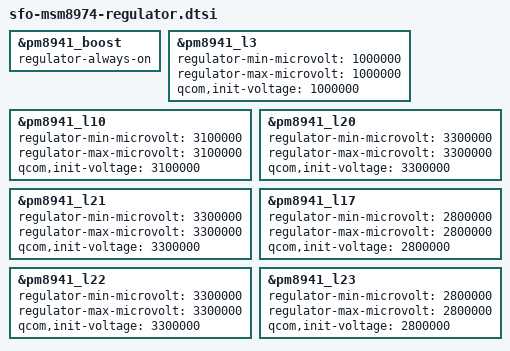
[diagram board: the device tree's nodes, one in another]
/* Copyright (c) 2012-2013, The Linux Foundation. All rights reserved.
 *
 * This program is free software; you can redistribute it and/or modify
 * it under the terms of the GNU General Public License version 2 and
 * only version 2 as published by the Free Software Foundation.
 *
 * This program is distributed in the hope that it will be useful,
 * but WITHOUT ANY WARRANTY; without even the implied warranty of
 * MERCHANTABILITY or FITNESS FOR A PARTICULAR PURPOSE.  See the
 * GNU General Public License for more details.
 */

&pm8941_boost {
            regulator-always-on;
};

&pm8941_l3 {
			regulator-min-microvolt = <1000000>;
			regulator-max-microvolt = <1000000>;
			qcom,init-voltage = <1000000>;
};

&pm8941_l10 {
			regulator-min-microvolt = <3100000>;
			regulator-max-microvolt = <3100000>;
			qcom,init-voltage = <3100000>;
};

&pm8941_l20 {
			regulator-min-microvolt = <3300000>;
			regulator-max-microvolt = <3300000>;
			qcom,init-voltage = <3300000>;
};

&pm8941_l21 {
			regulator-min-microvolt = <3300000>;
			regulator-max-microvolt = <3300000>;
			qcom,init-voltage = <3300000>;
};

&pm8941_l17 {
			regulator-min-microvolt = <2800000>;
			regulator-max-microvolt = <2800000>;
			qcom,init-voltage = <2800000>;
};

&pm8941_l22 {
			regulator-min-microvolt = <3300000>;
			regulator-max-microvolt = <3300000>;
			qcom,init-voltage = <3300000>;
};

&pm8941_l23 {
			regulator-min-microvolt = <2800000>;
			regulator-max-microvolt = <2800000>;
			qcom,init-voltage = <2800000>;
};
